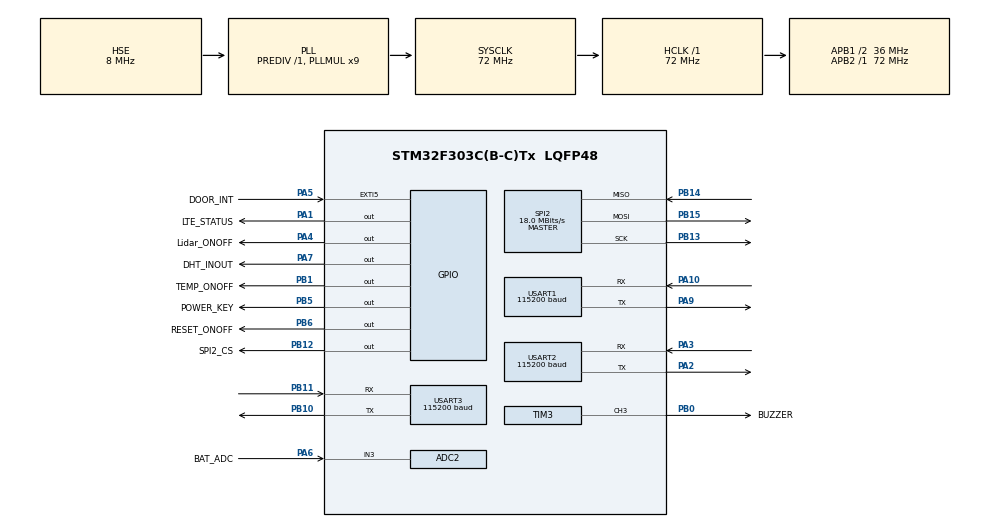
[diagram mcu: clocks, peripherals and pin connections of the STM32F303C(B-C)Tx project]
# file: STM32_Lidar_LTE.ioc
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ADC2.Channel-11\#ChannelRegularConversion=ADC_CHANNEL_3
ADC2.ContinuousConvMode=ENABLE
ADC2.DMAContinuousRequests=DISABLE
ADC2.EnableInjectedConversion=DISABLE
ADC2.EnableRegularConversion=ENABLE
ADC2.NbrOfConversionFlag=1
ADC2.Offset-11\#ChannelRegularConversion=0
ADC2.OffsetNumber-11\#ChannelRegularConversion=ADC_OFFSET_NONE
ADC2.Rank-11\#ChannelRegularConversion=1
ADC2.Rank1_Channel=ADC_CHANNEL_3
ADC2.SamplingTime-11\#ChannelRegularConversion=ADC_SAMPLETIME_19CYCLES_5
ADC2.SamplingTimeOPAMP-11\#ChannelRegularConversion=ADC_SAMPLETIME_61CYCLES_5
Dma.ADC2.0.Direction=DMA_PERIPH_TO_MEMORY
Dma.ADC2.0.Instance=DMA2_Channel1
Dma.ADC2.0.MemDataAlignment=DMA_MDATAALIGN_HALFWORD
Dma.ADC2.0.MemInc=DMA_MINC_ENABLE
Dma.ADC2.0.Mode=DMA_CIRCULAR
Dma.ADC2.0.PeriphDataAlignment=DMA_PDATAALIGN_HALFWORD
Dma.ADC2.0.PeriphInc=DMA_PINC_DISABLE
Dma.ADC2.0.Priority=DMA_PRIORITY_LOW
Dma.Request0=ADC2
Dma.Request1=USART2_RX
Dma.USART2_RX.1.Direction=DMA_PERIPH_TO_MEMORY
Dma.USART2_RX.1.Instance=DMA1_Channel6
Dma.USART2_RX.1.MemDataAlignment=DMA_MDATAALIGN_BYTE
Dma.USART2_RX.1.MemInc=DMA_MINC_ENABLE
Dma.USART2_RX.1.Mode=DMA_CIRCULAR
Dma.USART2_RX.1.PeriphDataAlignment=DMA_PDATAALIGN_BYTE
Dma.USART2_RX.1.PeriphInc=DMA_PINC_DISABLE
Dma.USART2_RX.1.Priority=DMA_PRIORITY_LOW
Mcu.Family=STM32F3
Mcu.Name=STM32F303C(B-C)Tx
Mcu.Package=LQFP48
NVIC.ADC1_2_IRQn=true\:2\:0\:true\:false\:true\:true\:true\:true
NVIC.DMA1_Channel6_IRQn=true\:7\:0\:true\:false\:true\:false\:true\:true
NVIC.DMA2_Channel1_IRQn=true\:0\:0\:false\:false\:true\:false\:true\:true
NVIC.EXTI9_5_IRQn=true\:1\:0\:true\:false\:true\:true\:true\:true
NVIC.PriorityGroup=NVIC_PRIORITYGROUP_4
NVIC.TIM1_TRG_COM_TIM17_IRQn=true\:14\:0\:true\:false\:true\:true\:true\:true
NVIC.TIM1_UP_TIM16_IRQn=true\:13\:0\:true\:false\:true\:true\:true\:true
NVIC.USART1_IRQn=true\:3\:0\:true\:false\:true\:true\:true\:true
NVIC.USART3_IRQn=true\:4\:0\:true\:false\:true\:true\:true\:true
PA1.GPIO_Label=LTE_STATUS
PA1.Signal=GPIO_Output
PA10.GPIO_PuPd=GPIO_PULLUP
PA10.Mode=Asynchronous
PA10.Signal=USART1_RX
PA13.Mode=Serial_Wire
PA13.Signal=SYS_JTMS-SWDIO
PA14.Mode=Serial_Wire
PA14.Signal=SYS_JTCK-SWCLK
PA2.Mode=Asynchronous
PA2.Signal=USART2_TX
PA3.Mode=Asynchronous
PA3.Signal=USART2_RX
PA4.GPIO_Label=Lidar_ONOFF
PA4.Signal=GPIO_Output
PA5.GPIO_Label=DOOR_INT
PA5.Signal=GPXTI5
PA6.GPIO_Label=BAT_ADC
PA6.Mode=IN3-Single-Ended
PA6.Signal=ADC2_IN3
PA7.GPIO_Label=DHT_INOUT
PA7.Signal=GPIO_Output
PA9.GPIO_PuPd=GPIO_PULLUP
PA9.Mode=Asynchronous
PA9.Signal=USART1_TX
PB0.GPIO_Label=BUZZER
PB0.Signal=S_TIM3_CH3
PB1.GPIO_Label=TEMP_ONOFF
PB1.Signal=GPIO_Output
PB10.Mode=Asynchronous
PB10.Signal=USART3_TX
PB11.Mode=Asynchronous
PB11.Signal=USART3_RX
PB12.GPIO_Label=SPI2_CS
PB12.Signal=GPIO_Output
PB13.Mode=Full_Duplex_Master
PB13.Signal=SPI2_SCK
PB14.Mode=Full_Duplex_Master
PB14.Signal=SPI2_MISO
PB15.Mode=Full_Duplex_Master
PB15.Signal=SPI2_MOSI
PB5.GPIO_Label=POWER_KEY
PB5.GPIO_ModeDefaultOutputPP=GPIO_MODE_OUTPUT_OD
PB5.GPIO_PuPd=GPIO_NOPULL
PB5.PinState=GPIO_PIN_SET
PB5.Signal=GPIO_Output
PB6.GPIO_FM6=__NULL
PB6.GPIO_Label=RESET_ONOFF
PB6.GPIO_ModeDefaultOutputPP=GPIO_MODE_OUTPUT_OD
PB6.GPIO_PuPd=GPIO_NOPULL
PB6.PinState=GPIO_PIN_SET
PB6.Signal=GPIO_Output
PC14-OSC32_IN.Mode=LSE-External-Oscillator
PC14-OSC32_IN.Signal=RCC_OSC32_IN
PC15-OSC32_OUT.Mode=LSE-External-Oscillator
PC15-OSC32_OUT.Signal=RCC_OSC32_OUT
PF0-OSC_IN.Mode=HSE-External-Oscillator
PF0-OSC_IN.Signal=RCC_OSC_IN
PF1-OSC_OUT.Mode=HSE-External-Oscillator
PF1-OSC_OUT.Signal=RCC_OSC_OUT
ProjectManager.HeapSize=0x200
ProjectManager.StackSize=0x400
ProjectManager.TargetToolchain=EWARM V8.32
RCC.AHBFreq_Value=72000000
RCC.APB1CLKDivider=RCC_HCLK_DIV2
RCC.APB1Freq_Value=36000000
RCC.APB1TimFreq_Value=72000000
RCC.APB2Freq_Value=72000000
RCC.APB2TimFreq_Value=72000000
RCC.CortexFreq_Value=72000000
RCC.HCLKFreq_Value=72000000
RCC.HSE_VALUE=8000000
RCC.HSI_VALUE=8000000
RCC.PLLMUL=RCC_PLL_MUL9
RCC.PLLSourceVirtual=RCC_PLLSOURCE_HSE
RCC.RTCClockSelection=RCC_RTCCLKSOURCE_HSE_DIV32
RCC.SYSCLKFreq_VALUE=72000000
RCC.SYSCLKSourceVirtual=RCC_SYSCLKSOURCE_PLLCLK
RCC.USBFreq_Value=72000000
RCC.Usart1ClockSelection=RCC_USART1CLKSOURCE_SYSCLK
RCC.Usart2ClockSelection=RCC_USART2CLKSOURCE_SYSCLK
RCC.Usart3ClockSelection=RCC_USART3CLKSOURCE_SYSCLK
SH.S_TIM3_CH3.0=TIM3_CH3,PWM Generation3 CH3
SPI2.BaudRatePrescaler=SPI_BAUDRATEPRESCALER_2
SPI2.CalculateBaudRate=18.0 MBits/s
SPI2.DataSize=SPI_DATASIZE_8BIT
SPI2.Direction=SPI_DIRECTION_2LINES
SPI2.Mode=SPI_MODE_MASTER
SPI2.VirtualType=VM_MASTER
TIM16.Period=100
TIM16.Prescaler=71
TIM17.Period=10000
TIM17.Prescaler=71
TIM3.Channel-PWM\ Generation3\ CH3=TIM_CHANNEL_3
TIM3.Period=300
TIM3.Prescaler=71
USART1.BaudRate=115200
USART1.VirtualMode-Asynchronous=VM_ASYNC
USART2.BaudRate=115200
USART2.VirtualMode-Asynchronous=VM_ASYNC
USART3.BaudRate=115200
USART3.VirtualMode-Asynchronous=VM_ASYNC
VP_RTC_VS_RTC_Activate.Mode=RTC_Enabled
VP_RTC_VS_RTC_Calendar.Mode=RTC_Calendar
VP_TIM16_VS_ClockSourceINT.Mode=Enable_Timer
VP_TIM17_VS_ClockSourceINT.Mode=Enable_Timer
board=custom

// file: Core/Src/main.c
/* USER CODE BEGIN Header */
/**
  ******************************************************************************
  * @file           : main.c
  * @brief          : Main program body
  ******************************************************************************
  * @attention
  *
  * Copyright (c) 2022 STMicroelectronics.
  * All rights reserved.
  *
  * This software is licensed under terms that can be found in the LICENSE file
  * in the root directory of this software component.
  * If no LICENSE file comes with this software, it is provided AS-IS.
  *
  ******************************************************************************
  */
/* USER CODE END Header */
#include "main.h"
#include "os.h"

ADC_HandleTypeDef hadc2;
DMA_HandleTypeDef hdma_adc2;
RTC_HandleTypeDef hrtc;
SPI_HandleTypeDef hspi2;
TIM_HandleTypeDef htim3;
TIM_HandleTypeDef htim16;
TIM_HandleTypeDef htim17;
UART_HandleTypeDef huart1;
UART_HandleTypeDef huart2;
UART_HandleTypeDef huart3;
DMA_HandleTypeDef hdma_usart2_rx;

void SystemClock_Config(void);
static void MX_GPIO_Init(void);
static void MX_DMA_Init(void);
static void MX_ADC2_Init(void);
static void MX_SPI2_Init(void);
static void MX_USART1_UART_Init(void);
static void MX_USART2_UART_Init(void);
static void MX_USART3_UART_Init(void);
static void MX_TIM3_Init(void);
static void MX_RTC_Init(void);
static void MX_TIM16_Init(void);
static void MX_TIM17_Init(void);

int main(void)
{

  /* MCU Configuration--------------------------------------------------------*/

  /* Reset of all peripherals, Initializes the Flash interface and the Systick. */
  HAL_Init();

  /* Configure the system clock */
  SystemClock_Config();

  /* Initialize all configured peripherals */
  MX_GPIO_Init();
  MX_DMA_Init();
  MX_ADC2_Init();
  MX_SPI2_Init();
  MX_USART1_UART_Init();
  MX_USART2_UART_Init();
  MX_USART3_UART_Init();
  MX_TIM3_Init();
  MX_RTC_Init();
  MX_TIM16_Init();
  MX_TIM17_Init();
  /* USER CODE BEGIN 2 */
  HAL_TIM_Base_Start_IT(&htim16);
  HAL_TIM_Base_Start_IT(&htim17);
  Os_Init_Task();
  HAL_Delay(2000);
  /* USER CODE END 2 */
  /* Infinite loop */
  while (1)
  {
    Os_Handler();
  }
}

void SystemClock_Config(void)
{
  RCC_OscInitTypeDef RCC_OscInitStruct = {0};
  RCC_ClkInitTypeDef RCC_ClkInitStruct = {0};
  RCC_PeriphCLKInitTypeDef PeriphClkInit = {0};

  /** Initializes the RCC Oscillators according to the specified parameters
  * in the RCC_OscInitTypeDef structure.
  */
  RCC_OscInitStruct.OscillatorType = RCC_OSCILLATORTYPE_HSE;
  RCC_OscInitStruct.HSEState = RCC_HSE_ON;
  RCC_OscInitStruct.HSEPredivValue = RCC_HSE_PREDIV_DIV1;
  RCC_OscInitStruct.HSIState = RCC_HSI_ON;
  RCC_OscInitStruct.PLL.PLLState = RCC_PLL_ON;
  RCC_OscInitStruct.PLL.PLLSource = RCC_PLLSOURCE_HSE;
  RCC_OscInitStruct.PLL.PLLMUL = RCC_PLL_MUL9;
  if (HAL_RCC_OscConfig(&RCC_OscInitStruct) != HAL_OK)
  {
    Error_Handler();
  }

  /** Initializes the CPU, AHB and APB buses clocks
  */
  RCC_ClkInitStruct.ClockType = RCC_CLOCKTYPE_HCLK|RCC_CLOCKTYPE_SYSCLK
                              |RCC_CLOCKTYPE_PCLK1|RCC_CLOCKTYPE_PCLK2;
  RCC_ClkInitStruct.SYSCLKSource = RCC_SYSCLKSOURCE_PLLCLK;
  RCC_ClkInitStruct.AHBCLKDivider = RCC_SYSCLK_DIV1;
  RCC_ClkInitStruct.APB1CLKDivider = RCC_HCLK_DIV2;
  RCC_ClkInitStruct.APB2CLKDivider = RCC_HCLK_DIV1;

  if (HAL_RCC_ClockConfig(&RCC_ClkInitStruct, FLASH_LATENCY_2) != HAL_OK)
  {
    Error_Handler();
  }
  PeriphClkInit.PeriphClockSelection = RCC_PERIPHCLK_USART1|RCC_PERIPHCLK_USART2
                              |RCC_PERIPHCLK_USART3|RCC_PERIPHCLK_RTC
                              |RCC_PERIPHCLK_ADC12;
  PeriphClkInit.Usart1ClockSelection = RCC_USART1CLKSOURCE_SYSCLK;
  PeriphClkInit.Usart2ClockSelection = RCC_USART2CLKSOURCE_SYSCLK;
  PeriphClkInit.Usart3ClockSelection = RCC_USART3CLKSOURCE_SYSCLK;
  PeriphClkInit.Adc12ClockSelection = RCC_ADC12PLLCLK_DIV1;
  PeriphClkInit.RTCClockSelection = RCC_RTCCLKSOURCE_HSE_DIV32;
  if (HAL_RCCEx_PeriphCLKConfig(&PeriphClkInit) != HAL_OK)
  {
    Error_Handler();
  }
}

static void MX_ADC2_Init(void)
{

  ADC_ChannelConfTypeDef sConfig = {0};

  /** Common config
  */
  hadc2.Instance = ADC2;
  hadc2.Init.ClockPrescaler = ADC_CLOCK_ASYNC_DIV1;
  hadc2.Init.Resolution = ADC_RESOLUTION_12B;
  hadc2.Init.ScanConvMode = ADC_SCAN_DISABLE;
  hadc2.Init.ContinuousConvMode = ENABLE;
  hadc2.Init.DiscontinuousConvMode = DISABLE;
  hadc2.Init.ExternalTrigConvEdge = ADC_EXTERNALTRIGCONVEDGE_NONE;
  hadc2.Init.ExternalTrigConv = ADC_SOFTWARE_START;
  hadc2.Init.DataAlign = ADC_DATAALIGN_RIGHT;
  hadc2.Init.NbrOfConversion = 1;
  hadc2.Init.DMAContinuousRequests = DISABLE;
  hadc2.Init.EOCSelection = ADC_EOC_SINGLE_CONV;
  hadc2.Init.LowPowerAutoWait = DISABLE;
  hadc2.Init.Overrun = ADC_OVR_DATA_OVERWRITTEN;
  if (HAL_ADC_Init(&hadc2) != HAL_OK)
  {
    Error_Handler();
  }

  /** Configure Regular Channel
  */
  sConfig.Channel = ADC_CHANNEL_3;
  sConfig.Rank = ADC_REGULAR_RANK_1;
  sConfig.SingleDiff = ADC_SINGLE_ENDED;
  sConfig.SamplingTime = ADC_SAMPLETIME_19CYCLES_5;
  sConfig.OffsetNumber = ADC_OFFSET_NONE;
  sConfig.Offset = 0;
  if (HAL_ADC_ConfigChannel(&hadc2, &sConfig) != HAL_OK)
  {
    Error_Handler();
  }

}

static void MX_RTC_Init(void)
{

  RTC_TimeTypeDef sTime = {0};
  RTC_DateTypeDef sDate = {0};

  /** Initialize RTC Only
  */
  hrtc.Instance = RTC;
  hrtc.Init.HourFormat = RTC_HOURFORMAT_24;
  hrtc.Init.AsynchPrediv = 124;
  hrtc.Init.SynchPrediv = 1999;
  hrtc.Init.OutPut = RTC_OUTPUT_DISABLE;
  hrtc.Init.OutPutPolarity = RTC_OUTPUT_POLARITY_HIGH;
  hrtc.Init.OutPutType = RTC_OUTPUT_TYPE_OPENDRAIN;
  if (HAL_RTC_Init(&hrtc) != HAL_OK)
  {
    Error_Handler();
  }

  /** Initialize RTC and set the Time and Date
  */
  sTime.Hours = 0;
  sTime.Minutes = 0;
  sTime.Seconds = 0;
  sTime.DayLightSaving = RTC_DAYLIGHTSAVING_NONE;
  sTime.StoreOperation = RTC_STOREOPERATION_RESET;
  if (HAL_RTC_SetTime(&hrtc, &sTime, RTC_FORMAT_BIN) != HAL_OK)
  {
    Error_Handler();
  }
  sDate.WeekDay = RTC_WEEKDAY_MONDAY;
  sDate.Month = RTC_MONTH_JANUARY;
  sDate.Date = 1;
  sDate.Year = 0;

  if (HAL_RTC_SetDate(&hrtc, &sDate, RTC_FORMAT_BIN) != HAL_OK)
  {
    Error_Handler();
  }

}

static void MX_SPI2_Init(void)
{

  /* SPI2 parameter configuration*/
  hspi2.Instance = SPI2;
  hspi2.Init.Mode = SPI_MODE_MASTER;
  hspi2.Init.Direction = SPI_DIRECTION_2LINES;
  hspi2.Init.DataSize = SPI_DATASIZE_8BIT;
  hspi2.Init.CLKPolarity = SPI_POLARITY_LOW;
  hspi2.Init.CLKPhase = SPI_PHASE_1EDGE;
  hspi2.Init.NSS = SPI_NSS_SOFT;
  hspi2.Init.BaudRatePrescaler = SPI_BAUDRATEPRESCALER_2;
  hspi2.Init.FirstBit = SPI_FIRSTBIT_MSB;
  hspi2.Init.TIMode = SPI_TIMODE_DISABLE;
  hspi2.Init.CRCCalculation = SPI_CRCCALCULATION_DISABLE;
  hspi2.Init.CRCPolynomial = 7;
  hspi2.Init.CRCLength = SPI_CRC_LENGTH_DATASIZE;
  hspi2.Init.NSSPMode = SPI_NSS_PULSE_ENABLE;
  if (HAL_SPI_Init(&hspi2) != HAL_OK)
  {
    Error_Handler();
  }

}

static void MX_TIM3_Init(void)
{

  TIM_MasterConfigTypeDef sMasterConfig = {0};
  TIM_OC_InitTypeDef sConfigOC = {0};

  htim3.Instance = TIM3;
  htim3.Init.Prescaler = 71;
  htim3.Init.CounterMode = TIM_COUNTERMODE_UP;
  htim3.Init.Period = 300;
  htim3.Init.ClockDivision = TIM_CLOCKDIVISION_DIV1;
  htim3.Init.AutoReloadPreload = TIM_AUTORELOAD_PRELOAD_DISABLE;
  if (HAL_TIM_PWM_Init(&htim3) != HAL_OK)
  {
    Error_Handler();
  }
  sMasterConfig.MasterOutputTrigger = TIM_TRGO_RESET;
  sMasterConfig.MasterSlaveMode = TIM_MASTERSLAVEMODE_DISABLE;
  if (HAL_TIMEx_MasterConfigSynchronization(&htim3, &sMasterConfig) != HAL_OK)
  {
    Error_Handler();
  }
  sConfigOC.OCMode = TIM_OCMODE_PWM1;
  sConfigOC.Pulse = 0;
  sConfigOC.OCPolarity = TIM_OCPOLARITY_HIGH;
  sConfigOC.OCFastMode = TIM_OCFAST_DISABLE;
  if (HAL_TIM_PWM_ConfigChannel(&htim3, &sConfigOC, TIM_CHANNEL_3) != HAL_OK)
  {
    Error_Handler();
  }
  HAL_TIM_MspPostInit(&htim3);

}

static void MX_TIM16_Init(void)
{

  htim16.Instance = TIM16;
  htim16.Init.Prescaler = 71;
  htim16.Init.CounterMode = TIM_COUNTERMODE_UP;
  htim16.Init.Period = 100;
  htim16.Init.ClockDivision = TIM_CLOCKDIVISION_DIV1;
  htim16.Init.RepetitionCounter = 0;
  htim16.Init.AutoReloadPreload = TIM_AUTORELOAD_PRELOAD_DISABLE;
  if (HAL_TIM_Base_Init(&htim16) != HAL_OK)
  {
    Error_Handler();
  }

}

static void MX_TIM17_Init(void)
{

  htim17.Instance = TIM17;
  htim17.Init.Prescaler = 71;
  htim17.Init.CounterMode = TIM_COUNTERMODE_UP;
  htim17.Init.Period = 10000;
  htim17.Init.ClockDivision = TIM_CLOCKDIVISION_DIV1;
  htim17.Init.RepetitionCounter = 0;
  htim17.Init.AutoReloadPreload = TIM_AUTORELOAD_PRELOAD_DISABLE;
  if (HAL_TIM_Base_Init(&htim17) != HAL_OK)
  {
    Error_Handler();
  }

}

static void MX_USART1_UART_Init(void)
{

  huart1.Instance = USART1;
  huart1.Init.BaudRate = 115200;
  huart1.Init.WordLength = UART_WORDLENGTH_8B;
  huart1.Init.StopBits = UART_STOPBITS_1;
  huart1.Init.Parity = UART_PARITY_NONE;
  huart1.Init.Mode = UART_MODE_TX_RX;
  huart1.Init.HwFlowCtl = UART_HWCONTROL_NONE;
  huart1.Init.OverSampling = UART_OVERSAMPLING_16;
  huart1.Init.OneBitSampling = UART_ONE_BIT_SAMPLE_DISABLE;
  huart1.AdvancedInit.AdvFeatureInit = UART_ADVFEATURE_NO_INIT;
  if (HAL_UART_Init(&huart1) != HAL_OK)
  {
    Error_Handler();
  }

}

static void MX_USART2_UART_Init(void)
{

  huart2.Instance = USART2;
  huart2.Init.BaudRate = 115200;
  huart2.Init.WordLength = UART_WORDLENGTH_8B;
  huart2.Init.StopBits = UART_STOPBITS_1;
  huart2.Init.Parity = UART_PARITY_NONE;
  huart2.Init.Mode = UART_MODE_TX_RX;
  huart2.Init.HwFlowCtl = UART_HWCONTROL_NONE;
  huart2.Init.OverSampling = UART_OVERSAMPLING_16;
  huart2.Init.OneBitSampling = UART_ONE_BIT_SAMPLE_DISABLE;
  huart2.AdvancedInit.AdvFeatureInit = UART_ADVFEATURE_NO_INIT;
  if (HAL_UART_Init(&huart2) != HAL_OK)
  {
    Error_Handler();
  }

}

static void MX_USART3_UART_Init(void)
{

  huart3.Instance = USART3;
  huart3.Init.BaudRate = 115200;
  huart3.Init.WordLength = UART_WORDLENGTH_8B;
  huart3.Init.StopBits = UART_STOPBITS_1;
  huart3.Init.Parity = UART_PARITY_NONE;
  huart3.Init.Mode = UART_MODE_TX_RX;
  huart3.Init.HwFlowCtl = UART_HWCONTROL_NONE;
  huart3.Init.OverSampling = UART_OVERSAMPLING_16;
  huart3.Init.OneBitSampling = UART_ONE_BIT_SAMPLE_DISABLE;
  huart3.AdvancedInit.AdvFeatureInit = UART_ADVFEATURE_NO_INIT;
  if (HAL_UART_Init(&huart3) != HAL_OK)
  {
    Error_Handler();
  }

}

static void MX_DMA_Init(void)
{

  /* DMA controller clock enable */
  __HAL_RCC_DMA2_CLK_ENABLE();
  __HAL_RCC_DMA1_CLK_ENABLE();

  /* DMA interrupt init */
  /* DMA1_Channel6_IRQn interrupt configuration */
  HAL_NVIC_SetPriority(DMA1_Channel6_IRQn, 7, 0);
  HAL_NVIC_EnableIRQ(DMA1_Channel6_IRQn);
  /* DMA2_Channel1_IRQn interrupt configuration */
  HAL_NVIC_SetPriority(DMA2_Channel1_IRQn, 0, 0);
  HAL_NVIC_EnableIRQ(DMA2_Channel1_IRQn);

}

static void MX_GPIO_Init(void)
{
  GPIO_InitTypeDef GPIO_InitStruct = {0};

  /* GPIO Ports Clock Enable */
  __HAL_RCC_GPIOC_CLK_ENABLE();
  __HAL_RCC_GPIOF_CLK_ENABLE();
  __HAL_RCC_GPIOA_CLK_ENABLE();
  __HAL_RCC_GPIOB_CLK_ENABLE();

  /*Configure GPIO pin Output Level */
  HAL_GPIO_WritePin(GPIOA, LTE_STATUS_Pin|Lidar_ONOFF_Pin|DHT_INOUT_Pin, GPIO_PIN_RESET);

  /*Configure GPIO pin Output Level */
  HAL_GPIO_WritePin(GPIOB, TEMP_ONOFF_Pin|SPI2_CS_Pin, GPIO_PIN_RESET);

  /*Configure GPIO pin Output Level */
  HAL_GPIO_WritePin(GPIOB, POWER_KEY_Pin|RESET_ONOFF_Pin, GPIO_PIN_SET);

  /*Configure GPIO pins : LTE_STATUS_Pin Lidar_ONOFF_Pin DHT_INOUT_Pin */
  GPIO_InitStruct.Pin = LTE_STATUS_Pin|Lidar_ONOFF_Pin|DHT_INOUT_Pin;
  GPIO_InitStruct.Mode = GPIO_MODE_OUTPUT_PP;
  GPIO_InitStruct.Pull = GPIO_NOPULL;
  GPIO_InitStruct.Speed = GPIO_SPEED_FREQ_LOW;
  HAL_GPIO_Init(GPIOA, &GPIO_InitStruct);

  /*Configure GPIO pin : DOOR_INT_Pin */
  GPIO_InitStruct.Pin = DOOR_INT_Pin;
  GPIO_InitStruct.Mode = GPIO_MODE_IT_RISING;
  GPIO_InitStruct.Pull = GPIO_NOPULL;
  HAL_GPIO_Init(DOOR_INT_GPIO_Port, &GPIO_InitStruct);

  /*Configure GPIO pins : TEMP_ONOFF_Pin SPI2_CS_Pin */
  GPIO_InitStruct.Pin = TEMP_ONOFF_Pin|SPI2_CS_Pin;
  GPIO_InitStruct.Mode = GPIO_MODE_OUTPUT_PP;
  GPIO_InitStruct.Pull = GPIO_NOPULL;
  GPIO_InitStruct.Speed = GPIO_SPEED_FREQ_LOW;
  HAL_GPIO_Init(GPIOB, &GPIO_InitStruct);

  /*Configure GPIO pins : POWER_KEY_Pin RESET_ONOFF_Pin */
  GPIO_InitStruct.Pin = POWER_KEY_Pin|RESET_ONOFF_Pin;
  GPIO_InitStruct.Mode = GPIO_MODE_OUTPUT_OD;
  GPIO_InitStruct.Pull = GPIO_NOPULL;
  GPIO_InitStruct.Speed = GPIO_SPEED_FREQ_LOW;
  HAL_GPIO_Init(GPIOB, &GPIO_InitStruct);

  /* EXTI interrupt init*/
  HAL_NVIC_SetPriority(EXTI9_5_IRQn, 0, 0);
  HAL_NVIC_EnableIRQ(EXTI9_5_IRQn);

}

void Error_Handler(void)
{
  __disable_irq();
  while (1)
  {
  }
}
